# ESP32-C5 register map
Vendor: ESPRESSIF SYSTEMS (SHANGHAI) CO., LTD.; Series: ESP32 C-Series; File version: 1
CPU: RV32IMAC r0p0, little endian, no MPU, no FPU, 0 interrupt priority bits
Address unit: 32 bits
Registers are 32-bit, read-write, reset 0x0 unless marked. A register's access mark holds for its fields unless they carry their own. Offsets are from the block's base; [hi:lo] are bit positions; lines under a group give offsets from that group; {n}, {i} and the like mark numbered series.

## LP_APM0 — LP_APM0 Peripheral
Base 0x600B3800
0x00 REGION_FILTER_EN reset 0x1 — Region filter enable register
  [3:0] REGION_FILTER_EN — Configure bit 0 (0-3) to enable region 0.\\ 0: disable \\ 1: enable \\
{0x4+0xC*i} REGION{i}_ADDR_START (i=0..3) — Region address register
  [31:0] REGION_ADDR_START — Configures start address of region %s.
{0x8+0xC*i} REGION{i}_ADDR_END (i=0..3) reset 0xFFFFFFFF — Region address register
  [31:0] REGION_ADDR_END — Configures end address of region %s.
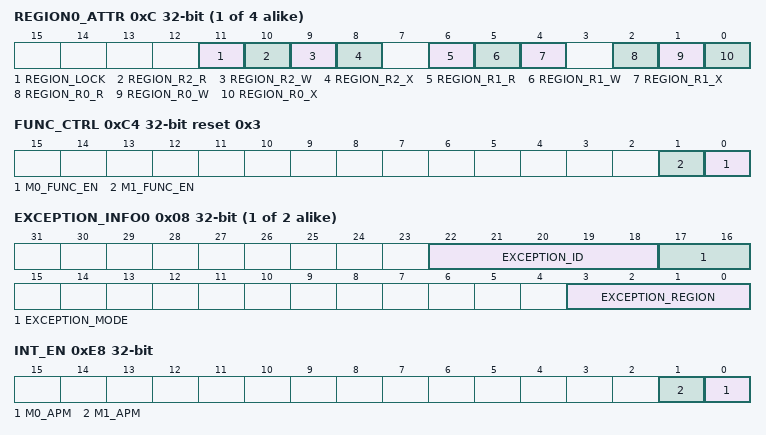
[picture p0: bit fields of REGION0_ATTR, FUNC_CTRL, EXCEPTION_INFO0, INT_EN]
{0xC+0xC*i} REGION{i}_ATTR (i=0..3) — Region access authority attribute register
  [11] REGION_LOCK — Set 1 to lock region0 configuration
  [10] REGION_R2_R — Configures the read authority of REE_MODE 2 in region %s.
  [9] REGION_R2_W — Configures the write authority of REE_MODE 2 in region %s.
  [8] REGION_R2_X — Configures the execution authority of REE_MODE 2 in region %s.
  [6] REGION_R1_R — Configures the read authority of REE_MODE 1 in region %s.
  [5] REGION_R1_W — Configures the write authority of REE_MODE 1 in region %s.
  [4] REGION_R1_X — Configures the execution authority of REE_MODE 1 in region %s.
  [2] REGION_R0_R — Configures the read authority of REE_MODE 0 in region %s.
  [1] REGION_R0_W — Configures the write authority of REE_MODE 0 in region %s.
  [0] REGION_R0_X — Configures the execution authority of REE_MODE 0 in region %s.
0xC4 FUNC_CTRL reset 0x3 — APM function control register
  [n] M{n}_FUNC_EN (n=0..1) — PMS M{n} function enable
{0xC8+0x10*i} M{i} (i=0..1) group — Cluster M{i}, containing M?_STATUS, M?_STATUS_CLR, M?_EXCEPTION_INFO0, M?_EXCEPTION_INFO1
  0x00 STATUS ro — M0 status register
    [1:0] EXCEPTION_STATUS — Represents exception status.\\ bit0: 1 represents authority_exception \\ bit1: 1 represents space_exception \\
  0x04 STATUS_CLR wo — M0 status clear register
    [0] EXCEPTION_STATUS_CLR — Configures to clear exception status.
  0x08 EXCEPTION_INFO0 ro — M0 exception_info0 register
    [22:18] EXCEPTION_ID — Represents exception id information.
    [17:16] EXCEPTION_MODE — Represents exception mode.
    [3:0] EXCEPTION_REGION — Represents exception region.
  0x0C EXCEPTION_INFO1 ro — M0 exception_info1 register
    [31:0] EXCEPTION_ADDR — Represents exception addr.
0xE8 INT_EN — APM interrupt enable register
  [n] M{n}_APM (n=0..1) — Configures to enable APM M{n} interrupt.\\ 0: disable \\ 1: enable \\
0xEC CLOCK_GATE reset 0x1 — clock gating register
  [0] CLK_EN — Configures whether to keep the clock always on.\\ 0: enable automatic clock gating \\ 1: keep the clock always on \\
0xFC DATE — Version control register

## LP_APM — LP_APM Peripheral
Base 0x600B3800
0x00 REGION_FILTER_EN
  [7:0] REGION_FILTER_EN — Configure bit $n (0-7) to enable region $n (0-7). 0: Disable 1: Enable
{0x4+0xC*i} REGION{i} (i=0..7) group — Cluster REGION{i}, containing REGION*_ADDR_START, REGION*_ADDR_END, REGION*_ATTR
  0x00 ADDR_START — Region address register
    [31:0] ADDR_START — Configures the start address of region 0.
  0x04 ADDR_END — Region address register
    [31:0] ADDR_END — Configures the end address of region 0.
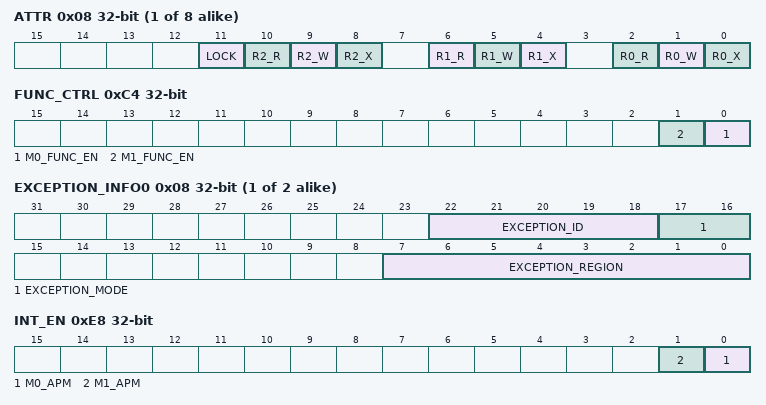
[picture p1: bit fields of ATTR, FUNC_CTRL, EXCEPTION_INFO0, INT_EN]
  0x08 ATTR — Region access permissions configuration register
    [11] LOCK — Configures to lock the value of region 0 configuration registers (LP_APM_REGION0_ADDR_START_REG, LP_APM_REGION0_ADDR_END_REG and LP_APM_REGION0_ATTR_REG). 0: Do not lock 1: Lock
    [4n+2] R{n}_R (n=0..2) — Configures the write permission in region X
    [4n+1] R{n}_W (n=0..2) — Configures the write permission in region X
    [4n] R{n}_X (n=0..2) — Configures the execution permission in region X
0xC4 FUNC_CTRL — APM access path permission management register
  [n] M{n}_FUNC_EN (n=0..1) — Configures to enable permission management for LP_APM_CTRL M{n}.
{0xC8+0x10*i} M{i} (i=0..1) group — Cluster M{i}, containing M?_STATUS, M?_STATUS_CLR, M?_EXCEPTION_INFO0, M?_EXCEPTION_INFO1
  0x00 STATUS ro — LP_APM_CTRL M0 status register
    [1:0] EXCEPTION_STATUS — Represents exception status. bit0: 1 represents permission restrictions bit1: 1 represents address out of bounds
  0x04 STATUS_CLR wo — LP_APM_CTRL M0 status clear register
    [0] EXCEPTION_STATUS_CLR — Configures to clear exception status.
  0x08 EXCEPTION_INFO0 ro — LP_APM_CTRL M0 exception information register
    [22:18] EXCEPTION_ID — Represents master ID when an exception occurs.
    [17:16] EXCEPTION_MODE — Represents the master's security mode when an exception occurs.
    [7:0] EXCEPTION_REGION — Represents the region where an exception occurs.
  0x0C EXCEPTION_INFO1 ro — LP_APM_CTRL M0 exception information register
    [31:0] EXCEPTION_ADDR — Represents the access address when an exception occurs.
0xE8 INT_EN — LP_APM_CTRL M0/1 interrupt enable register
  [n] M{n}_APM (n=0..1) — Configures to enable LP_APM_CTRL M{n} interrupt. 0: Disable 1: Enable
0xEC CLOCK_GATE — Clock gating register
  [0] CLK_EN — Configures whether to keep the clock always on. 0: Enable automatic clock gating 1: Keep the clock always on
0xFC DATE — Version control register
